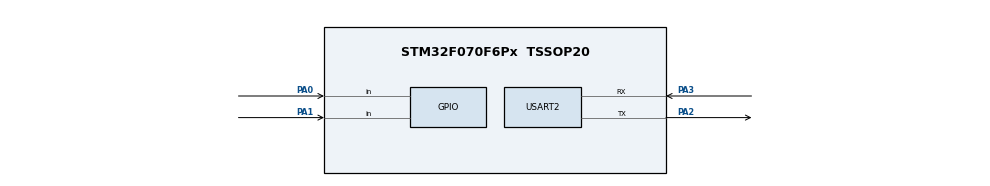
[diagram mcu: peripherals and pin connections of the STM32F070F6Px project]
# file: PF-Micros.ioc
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Mcu.Family=STM32F0
Mcu.Name=STM32F070F6Px
Mcu.Package=TSSOP20
NVIC.TIM16_IRQn=true\:0\:0\:false\:false\:true\:true\:true\:true
PA0.Signal=GPIO_Input
PA1.Signal=GPIO_Input
PA13.Mode=Serial_Wire
PA13.Signal=SYS_SWDIO
PA14.Mode=Serial_Wire
PA14.Signal=SYS_SWCLK
PA2.Mode=Asynchronous
PA2.Signal=USART2_TX
PA3.Mode=Asynchronous
PA3.Signal=USART2_RX
ProjectManager.HeapSize=0x200
ProjectManager.StackSize=0x400
ProjectManager.TargetToolchain=STM32CubeIDE
TIM16.Period=1667
TIM16.Prescaler=47999
USART2.VirtualMode-Asynchronous=VM_ASYNC
VP_TIM16_VS_ClockSourceINT.Mode=Enable_Timer
board=custom

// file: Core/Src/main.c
/* USER CODE BEGIN Header */
/**
  ******************************************************************************
  * @file           : main.c
  * @brief          : Este projeto corresponde ao projeto final da cadeira
  * de sistemas microprocessados, feito por Ermeson Alves, Luis Carlos,
  * Carlos Victor e Guilherme Noronha
  ******************************************************************************
  * @attention
  *
  * Copyright (c) 2022 STMicroelectronics.
  * All rights reserved.
  *
  * This software is licensed under terms that can be found in the LICENSE file
  * in the root directory of this software component.
  * If no LICENSE file comes with this software, it is provided AS-IS.
  *
  ******************************************************************************
  */
/* USER CODE END Header */
#include "main.h"

TIM_HandleTypeDef htim16;

UART_HandleTypeDef huart2;

unsigned int numero_entraram = 0;
unsigned int numero_sairam = 0;
unsigned int numero_atual = 0;

void SystemClock_Config(void);
static void MX_GPIO_Init(void);
static void MX_TIM16_Init(void);
static void MX_USART2_UART_Init(void);

/* USER CODE BEGIN 0 */

void HAL_TIM_PeriodElapsedCallback(TIM_HandleTypeDef *htim){
	char message[144];

	int len = sprintf(message,"\r\nNos ultimos 10s:\r\nNumero de pessoas atualmente dentro do ambiente = %d\r\nNumero de pessoas que entraram = %d\r\nNumero de pessoas que sairam = %d\r\n"
			, numero_atual, numero_entraram, numero_sairam);

	HAL_UART_Transmit(&huart2,(uint8_t *) message,sizeof(message),100);// Sending in normal mode

	numero_entraram = 0;
	numero_sairam = 0;
}

/* USER CODE END 0 */

int main(void)
{
  /* MCU Configuration--------------------------------------------------------*/

  /* Reset of all peripherals, Initializes the Flash interface and the Systick. */
  HAL_Init();

  /* Configure the system clock */
  SystemClock_Config();

  /* Initialize all configured peripherals */
  MX_GPIO_Init();
  MX_TIM16_Init();
  MX_USART2_UART_Init();

  HAL_TIM_Base_Start_IT(&htim16);

  while (1)
  {
	/* */

	  /* ENTRADA DE PESSOAS */
      if(!HAL_GPIO_ReadPin(GPIOA, GPIO_PIN_0)) {
    	  numero_entraram++;
    	  numero_atual++;
    	  HAL_Delay(1000);
      }

      /* SAIDA DE PESSOAS */
      if(!HAL_GPIO_ReadPin(GPIOA, GPIO_PIN_1)) {
          numero_sairam++;
          numero_atual--;
          HAL_Delay(1000);
      }

  }
}

void SystemClock_Config(void)
{
  RCC_OscInitTypeDef RCC_OscInitStruct = {0};
  RCC_ClkInitTypeDef RCC_ClkInitStruct = {0};

  /** Initializes the RCC Oscillators according to the specified parameters
  * in the RCC_OscInitTypeDef structure.
  */
  RCC_OscInitStruct.OscillatorType = RCC_OSCILLATORTYPE_HSI;
  RCC_OscInitStruct.HSIState = RCC_HSI_ON;
  RCC_OscInitStruct.HSICalibrationValue = RCC_HSICALIBRATION_DEFAULT;
  RCC_OscInitStruct.PLL.PLLState = RCC_PLL_NONE;
  if (HAL_RCC_OscConfig(&RCC_OscInitStruct) != HAL_OK)
  {
    Error_Handler();
  }

  /** Initializes the CPU, AHB and APB buses clocks
  */
  RCC_ClkInitStruct.ClockType = RCC_CLOCKTYPE_HCLK|RCC_CLOCKTYPE_SYSCLK
                              |RCC_CLOCKTYPE_PCLK1;
  RCC_ClkInitStruct.SYSCLKSource = RCC_SYSCLKSOURCE_HSI;
  RCC_ClkInitStruct.AHBCLKDivider = RCC_SYSCLK_DIV1;
  RCC_ClkInitStruct.APB1CLKDivider = RCC_HCLK_DIV1;

  if (HAL_RCC_ClockConfig(&RCC_ClkInitStruct, FLASH_LATENCY_0) != HAL_OK)
  {
    Error_Handler();
  }
}

static void MX_TIM16_Init(void)
{

  htim16.Instance = TIM16;
  htim16.Init.Prescaler = 47999;
  htim16.Init.CounterMode = TIM_COUNTERMODE_UP;
  htim16.Init.Period = 1667;
  htim16.Init.ClockDivision = TIM_CLOCKDIVISION_DIV1;
  htim16.Init.RepetitionCounter = 0;
  htim16.Init.AutoReloadPreload = TIM_AUTORELOAD_PRELOAD_DISABLE;
  if (HAL_TIM_Base_Init(&htim16) != HAL_OK)
  {
    Error_Handler();
  }

}

static void MX_USART2_UART_Init(void)
{

  huart2.Instance = USART2;
  huart2.Init.BaudRate = 38400;
  huart2.Init.WordLength = UART_WORDLENGTH_8B;
  huart2.Init.StopBits = UART_STOPBITS_1;
  huart2.Init.Parity = UART_PARITY_NONE;
  huart2.Init.Mode = UART_MODE_TX_RX;
  huart2.Init.HwFlowCtl = UART_HWCONTROL_NONE;
  huart2.Init.OverSampling = UART_OVERSAMPLING_16;
  huart2.Init.OneBitSampling = UART_ONE_BIT_SAMPLE_DISABLE;
  huart2.AdvancedInit.AdvFeatureInit = UART_ADVFEATURE_NO_INIT;
  if (HAL_UART_Init(&huart2) != HAL_OK)
  {
    Error_Handler();
  }

}

static void MX_GPIO_Init(void)
{
  GPIO_InitTypeDef GPIO_InitStruct = {0};

  /* GPIO Ports Clock Enable */
  __HAL_RCC_GPIOA_CLK_ENABLE();

  /*Configure GPIO pins : PA0 PA1 */
  GPIO_InitStruct.Pin = GPIO_PIN_0|GPIO_PIN_1;
  GPIO_InitStruct.Mode = GPIO_MODE_INPUT;
  GPIO_InitStruct.Pull = GPIO_NOPULL;
  HAL_GPIO_Init(GPIOA, &GPIO_InitStruct);

}

void Error_Handler(void)
{
  __disable_irq();
  while (1)
  {
  }
}
